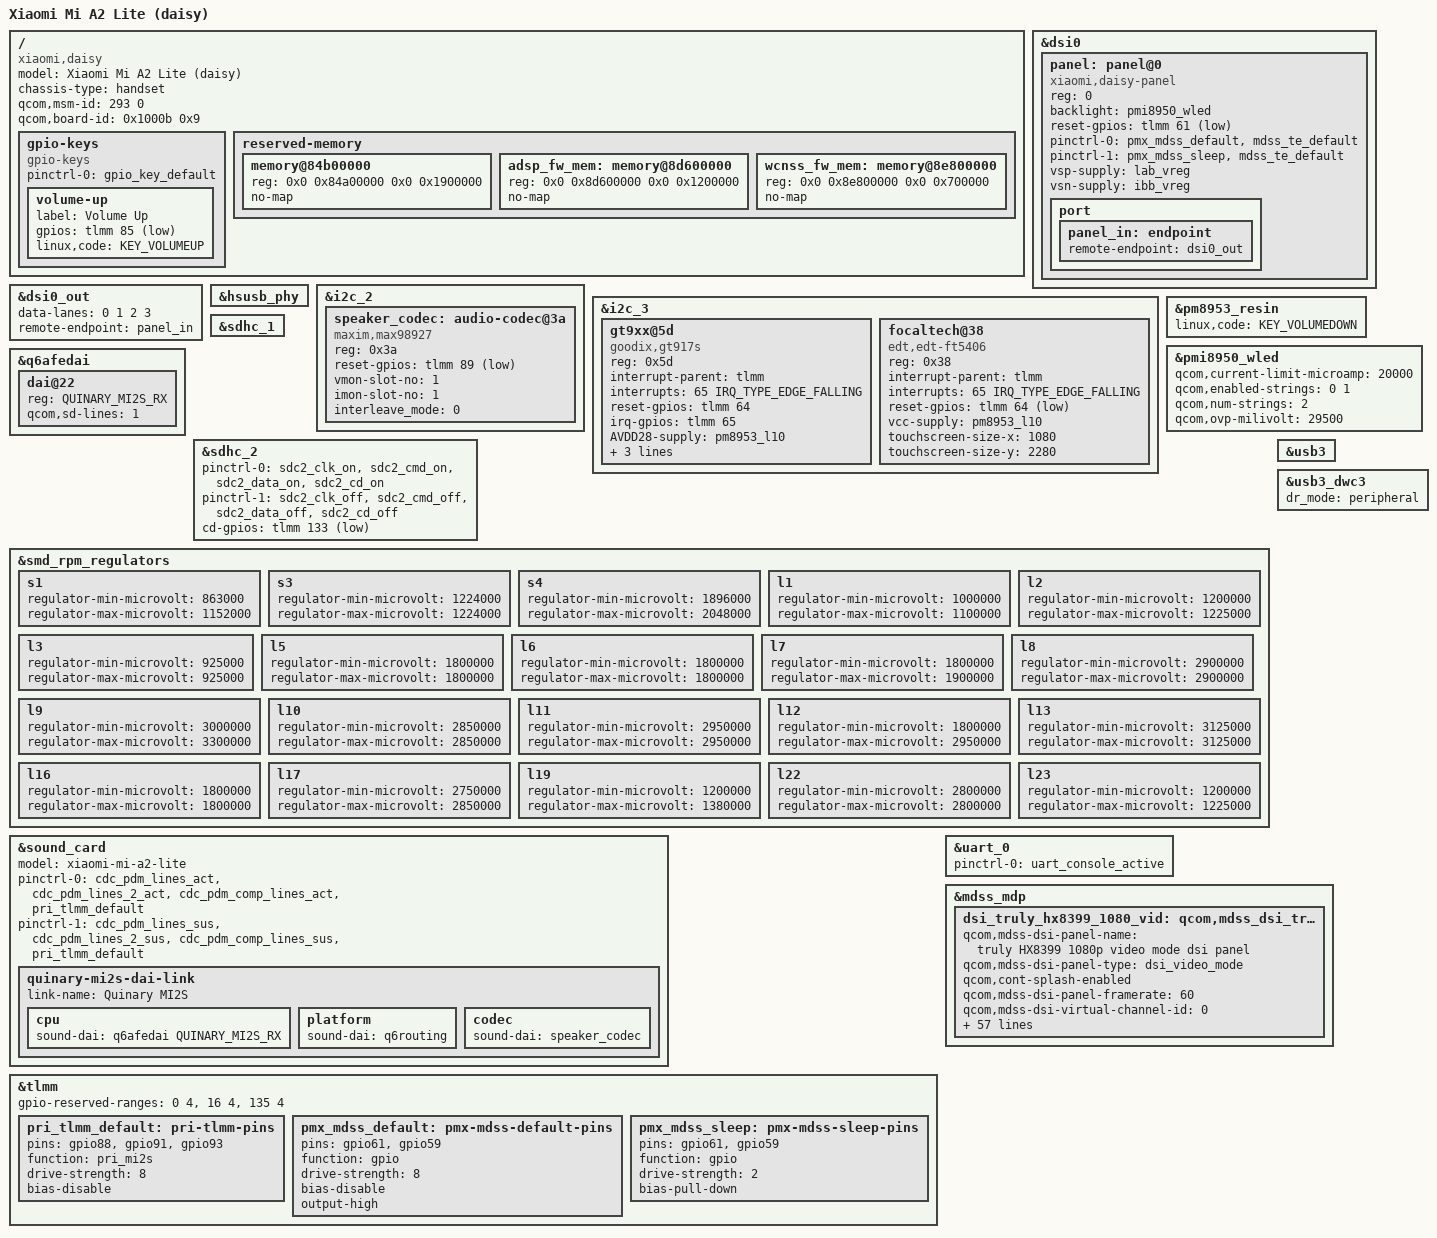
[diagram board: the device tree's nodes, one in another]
/* Copyright (c) 2022 The Linux Foundation. All rights reserved.
 *
 * This program is free software; you can redistribute it and/or modify
 * it under the terms of the GNU General Public License version 2 and
 * only version 2 as published by the Free Software Foundation.
 *
 * This program is distributed in the hope that it will be useful,
 * but WITHOUT ANY WARRANTY; without even the implied warranty of
 * MERCHANTABILITY or FITNESS FOR A PARTICULAR PURPOSE.  See the
 * GNU General Public License for more details.
 */
/dts-v1/;

#include "msm8953-pm8953.dtsi"
#include "pmi8950.dtsi"

#include <dt-bindings/gpio/gpio.h>
#include <dt-bindings/leds/common.h>

/ {
	compatible = "xiaomi,daisy", "qcom,msm8953";
	model = "Xiaomi Mi A2 Lite (daisy)";
	chassis-type = "handset";
	qcom,msm-id = <293 0>;
	qcom,board-id= <0x1000b 0x9>;

	gpio-keys {
		compatible = "gpio-keys";

		pinctrl-names = "default";
		pinctrl-0 = <&gpio_key_default>;

		volume-up {
			label = "Volume Up";
			gpios = <&tlmm 85 GPIO_ACTIVE_LOW>;
			linux,code = <KEY_VOLUMEUP>;
		};
	};

	reserved-memory {
		/delete-node/memory@85b00000;

		memory@84b00000 {
			reg = <0x0 0x84a00000 0x0 0x1900000>;
			no-map;
		};

		adsp_fw_mem: memory@8d600000 {
			reg = <0x0 0x8d600000 0x0 0x1200000>;
			no-map;
		};

		/delete-node/memory@8e700000;
		wcnss_fw_mem: memory@8e800000 {
			reg = <0x0 0x8e800000 0x0 0x700000>;
			no-map;
		};

		/*ramoops@9f00000 { // TODO Enable?
			compatible = "ramoops";
			reg = <0x0 0x9f00000 0x0 0x100000>;
			record-size = <0x10000>;
			console-size = <0x60000>;
			ftrace-size = <0x10000>;
			pmsg-size = <0x20000>;
			status = "okay";
		};*/
	};
};

&dsi0 {
	panel: panel@0 {
		compatible = "xiaomi,daisy-panel";
		reg = <0>;

		backlight = <&pmi8950_wled>;

		reset-gpios = <&tlmm 61 GPIO_ACTIVE_LOW>;

		pinctrl-names = "default", "sleep";
		pinctrl-0 = <&pmx_mdss_default &mdss_te_default>;
		pinctrl-1 = <&pmx_mdss_sleep &mdss_te_default>;

		vsp-supply = <&lab_vreg>;
		vsn-supply = <&ibb_vreg>;

		port {
			panel_in: endpoint {
				remote-endpoint = <&dsi0_out>;
			};
		};
	};
};

&dsi0_out {
	data-lanes = <0 1 2 3>;
	remote-endpoint = <&panel_in>;
};

&hsusb_phy {
	status = "okay";
};

&i2c_2 {
	status = "okay";

	speaker_codec: audio-codec@3a {
		compatible = "maxim,max98927";
		reg = <0x3a>;

		reset-gpios = <&tlmm 89 GPIO_ACTIVE_LOW>;

		vmon-slot-no = <1>;
		imon-slot-no = <1>;
		interleave_mode = <0>;

		#sound-dai-cells = <0>;
	};
};

&i2c_3 {
	status = "okay";

	gt9xx@5d {
		compatible = "goodix,gt917s";
		reg = <0x5d>;

		interrupt-parent = <&tlmm>;
		interrupts = <65 IRQ_TYPE_EDGE_FALLING>;

		reset-gpios = <&tlmm 64 GPIO_ACTIVE_HIGH>;
		irq-gpios = <&tlmm 65 GPIO_ACTIVE_HIGH>;

		AVDD28-supply = <&pm8953_l10>;
		VDDIO-supply = <&pm8953_l6>;

		touchscreen-size-x = <1080>;
		touchscreen-size-y = <2280>;
	};

	focaltech@38 {
		compatible = "edt,edt-ft5406", "edt,edt-ft5x06";
		reg = <0x38>;

		interrupt-parent = <&tlmm>;
		interrupts = <65 IRQ_TYPE_EDGE_FALLING>;

		reset-gpios = <&tlmm 64 GPIO_ACTIVE_LOW>;

		vcc-supply = <&pm8953_l10>;

		touchscreen-size-x = <1080>;
		touchscreen-size-y = <2280>;
	};
};

&pm8953_resin {
	status = "okay";
	linux,code = <KEY_VOLUMEDOWN>;
};

&pmi8950_wled {
	status = "okay";

	qcom,current-limit-microamp = <20000>;
	qcom,enabled-strings = <0 1>;
	qcom,num-strings = <2>;
	qcom,ovp-milivolt = <29500>;
};

&q6afedai {
	dai@22 {
		reg = <QUINARY_MI2S_RX>;
		qcom,sd-lines = <1>;
	};
};

&sdhc_1 {
	status = "okay";
};

&sdhc_2 {
	status = "okay";

	pinctrl-names = "default", "sleep";
	pinctrl-0 = <&sdc2_clk_on &sdc2_cmd_on &sdc2_data_on &sdc2_cd_on>;
	pinctrl-1 = <&sdc2_clk_off &sdc2_cmd_off &sdc2_data_off &sdc2_cd_off>;

	cd-gpios = <&tlmm 133 GPIO_ACTIVE_LOW>;
};

&smd_rpm_regulators {
	//TODO Supplies

	s1 {
		regulator-min-microvolt = <863000>;
		regulator-max-microvolt = <1152000>;
	};

	s3 {
		regulator-min-microvolt = <1224000>;
		regulator-max-microvolt = <1224000>;
	};

	s4 {
		regulator-min-microvolt = <1896000>;
		regulator-max-microvolt = <2048000>;
	};

	l1 {
		regulator-min-microvolt = <1000000>;
		regulator-max-microvolt = <1100000>;
	};

	l2 {
		regulator-min-microvolt = <1200000>;
		regulator-max-microvolt = <1225000>;
	};

	l3 {
		regulator-min-microvolt = <925000>;
		regulator-max-microvolt = <925000>;
	};

	l5 {
		regulator-min-microvolt = <1800000>;
		regulator-max-microvolt = <1800000>;
	};

	l6 {
		regulator-min-microvolt = <1800000>;
		regulator-max-microvolt = <1800000>;
	};

	l7 {
		regulator-min-microvolt = <1800000>;
		regulator-max-microvolt = <1900000>;
	};

	l8 {
		regulator-min-microvolt = <2900000>;
		regulator-max-microvolt = <2900000>;
	};

	l9 {
		regulator-min-microvolt = <3000000>;
		regulator-max-microvolt = <3300000>;
	};

	l10 {
		regulator-min-microvolt = <2850000>;
		regulator-max-microvolt = <2850000>;
	};

	l11 {
		regulator-min-microvolt = <2950000>;
		regulator-max-microvolt = <2950000>;
	};

	l12 {
		regulator-min-microvolt = <1800000>;
		regulator-max-microvolt = <2950000>;
	};

	l13 {
		regulator-min-microvolt = <3125000>;
		regulator-max-microvolt = <3125000>;
	};

	l16 {
		regulator-min-microvolt = <1800000>;
		regulator-max-microvolt = <1800000>;
	};

	l17 {
		regulator-min-microvolt = <2750000>;
		regulator-max-microvolt = <2850000>;
	};

	l19 {
		regulator-min-microvolt = <1200000>;
		regulator-max-microvolt = <1380000>;
	};

	l22 {
		regulator-min-microvolt = <2800000>;
		regulator-max-microvolt = <2800000>;
	};

	l23 {
		regulator-min-microvolt = <1200000>;
		regulator-max-microvolt = <1225000>;
	};
};

&sound_card {
	status = "okay";

	model = "xiaomi-mi-a2-lite";

	pinctrl-names = "default", "sleep";
	pinctrl-0 = <&cdc_pdm_lines_act &cdc_pdm_lines_2_act &cdc_pdm_comp_lines_act &pri_tlmm_default>;
	pinctrl-1 = <&cdc_pdm_lines_sus &cdc_pdm_lines_2_sus &cdc_pdm_comp_lines_sus &pri_tlmm_default>;

	quinary-mi2s-dai-link {
		link-name = "Quinary MI2S";
		cpu {
			sound-dai = <&q6afedai QUINARY_MI2S_RX>;
		};

		platform {
			sound-dai = <&q6routing>;
		};

		codec {
			sound-dai = <&speaker_codec>;
		};
	};
};

&tlmm {
	gpio-reserved-ranges = <0 4>, <16 4>, <135 4>;

	pri_tlmm_default: pri-tlmm-pins {
		pins = "gpio88", "gpio91", "gpio93";
		function = "pri_mi2s";
		drive-strength = <8>;
		bias-disable;
	};

	pmx_mdss_default: pmx-mdss-default-pins {
		pins = "gpio61", "gpio59";
		function = "gpio";
		drive-strength = <8>;
		bias-disable;
		output-high;
	};

	pmx_mdss_sleep: pmx-mdss-sleep-pins {
		pins = "gpio61", "gpio59";
		function = "gpio";
		drive-strength = <2>;
		bias-pull-down;
	};
};

&uart_0 {
	status = "okay";
	pinctrl-names = "default";
	pinctrl-0 = <&uart_console_active>;
};

&usb3 {
	status = "okay";
};

&usb3_dwc3 {
	dr_mode = "peripheral";
};

&mdss_mdp {
	dsi_truly_hx8399_1080_vid: qcom,mdss_dsi_truly_hx8399_1080p_video {
		qcom,mdss-dsi-panel-name = "truly HX8399 1080p video mode dsi panel";
		qcom,mdss-dsi-panel-type = "dsi_video_mode";
		qcom,cont-splash-enabled;
		qcom,mdss-dsi-panel-framerate = <60>;
		qcom,mdss-dsi-virtual-channel-id = <0>;
		qcom,mdss-dsi-stream = <0>;
		qcom,mdss-dsi-panel-width = <1080>;
		qcom,mdss-dsi-panel-height = <1920>;
		qcom,mdss-dsi-h-front-porch = <90>;
		qcom,mdss-dsi-h-back-porch = <60>;
		qcom,mdss-dsi-h-pulse-width = <20>;
		qcom,mdss-dsi-h-sync-skew = <0>;
		qcom,mdss-dsi-v-front-porch = <9>;
		qcom,mdss-dsi-v-back-porch = <3>;
		qcom,mdss-dsi-v-pulse-width = <4>;
		qcom,mdss-dsi-h-left-border = <0>;
		qcom,mdss-dsi-h-right-border = <0>;
		qcom,mdss-dsi-v-top-border = <0>;
		qcom,mdss-dsi-v-bottom-border = <0>;
		qcom,mdss-dsi-bpp = <24>;
		qcom,mdss-dsi-underflow-color = <0xff>;
		qcom,mdss-dsi-border-color = <0>;
		qcom,mdss-dsi-h-sync-pulse = <0>;
		qcom,mdss-dsi-traffic-mode = "burst_mode";
		qcom,mdss-dsi-bllp-eof-power-mode;
		qcom,mdss-dsi-bllp-power-mode;
		qcom,mdss-dsi-lane-0-state;
		qcom,mdss-dsi-lane-1-state;
		qcom,mdss-dsi-lane-2-state;
		qcom,mdss-dsi-lane-3-state;
		qcom,mdss-dsi-panel-timings = [f9 3d 34 00 58 4d 36 3f 53 03 04 00];
		qcom,mdss-dsi-t-clk-post = <0x02>;
		qcom,mdss-dsi-t-clk-pre = <0x2d>;
		qcom,mdss-dsi-bl-min-level = <160>;
		qcom,mdss-dsi-bl-max-level = <3562>;
		qcom,mdss-dsi-dma-trigger = "trigger_sw";
		qcom,mdss-dsi-mdp-trigger = "none";
                qcom,mdss-pan-physical-width-dimension = <69>;
                qcom,mdss-pan-physical-height-dimension = <122>;
		qcom,mdss-dsi-on-command = [
			39 01 00 00 00 00 04
			B9 FF 83 99
			39 01 00 00 00 00 10
			B1 00 04 6C 8C 01 32
			22 11 11 58 62 56 73
			02 02
			39 01 00 00 00 00 0c
			B2 00 80 80 AE 05 07
			5A 11 10 10 00
			39 01 00 00 00 00 2d
			B4 00 ff 00 A0 00 A0
			00 00 08 00 00 02 00
			24 02 04 0C 33 06 00
			00 00 a2 88 00 A0 00
			A0 00 00 08 00 00 02
			00 24 02 04 0C 00 00
			00 a2 08
			39 01 00 00 00 00 22
			D3 00 00 00 00 00 00
			06 00 32 10 05 00 05
			00 00 00 00 00 00 00
			00 00 00 01 00 05 05
			03 00 00 00 05 40
			39 01 00 00 00 00 21
			D5 18 18 00 00 00 00
			00 00 19 19 18 18 00
			00 00 00 00 00 00 00
			01 00 03 02 20 21 2F
			2F 30 30 31 31
			39 01 00 00 00 00 21
			D6 18 18 40 40 40 40
			40 40 18 18 19 19 40
			40 40 40 40 40 40 40
			02 03 00 01 21 20 2F
			2F 30 30 31 31
			39 01 00 00 00 00 11
			D8 00 00 00 00 00 00
			00 00 00 00 00 00 00
			00 00 00
			39 01 00 00 00 00 02
			BD 01
			39 01 00 00 00 00 11
			D8 00 00 00 00 00 00
			00 00 00 00 00 00 00
			00 00 00
			39 01 00 00 00 00 02
			BD 02
			39 01 00 00 00 00 09
			D8 c0 00 0a 3f c0 00
			0a 3f
			39 01 00 00 00 00 02
			BD 00
			39 01 00 00 00 00 37
			E0 01 14 20 19 3C 44
			52 4F 57 61 69 6E 75
			7B 83 85 89 90 92 97
			8B 98 9B 51 4E 59 65
			01 14 20 19 3C 44 52
			4F 57 61 69 6F 75 7C
			83 86 8A 91 92 98 8B
			98 9C 51 4E 5A 65
			39 01 00 00 00 00 02
			BD 00
			39 01 00 00 00 00 2C
			C1 01 00 08 10 18 20
			27 2F 37 3F 47 4F 56
			5F 67 6E 76 7E 86 8E
			96 9E A6 AF B6 BE C6
			CD D6 DE E7 EF F8 FF
			15 87 86 0F A9 11 0E
			12 C0
			39 01 00 00 00 00 02
			BD 01
			39 01 00 00 00 00 2B
			C1 00 08 10 18 20 27
			2F 38 3F 47 4F 57 5F
			67 6F 77 7F 87 90 98
			9F A7 AF B7 BE C7 CE
			D6 DE E7 EF F7 FF 05
			58 AA BA B0 94 CE C7
			C0
			39 01 00 00 00 00 02
			BD 02
			39 01 00 00 00 00 2B
			C1 00 08 0F 17 1F 27
			30 39 41 49 52 5A 62
			6B 73 7B 83 8C 93 9B
			A3 AB B3 BB C3 CB D3
			DA E2 EA F2 F9 FF 0F
			E6 71 D9 4E ED 82 82
			C0
			39 01 00 00 00 00 02
			BD 00
			39 01 00 00 00 00 02
			CC 08
			39 01 00 00 00 00 02
			D2 22
			39 01 00 00 00 00 04
			C9 03 00 0A
			39 01 00 00 00 00 03
			51 00 00
			15 01 00 00 00 00 02
			53 24
			15 01 00 00 0a 00 02
			55 00
			05 01 00 00 00 00 02
			34 00
			05 01 00 00 78 00 02
			11 00
			39 01 00 00 00 00 02
			D0 39
			05 01 00 00 00 00 02
			29 00
		];
		qcom,mdss-dsi-off-command = [
			05 01 00 00 32 00 02
			28 00
			05 01 00 00 64 00 02
			10 00
			39 01 00 00 00 00 04
			B9 ff 83 99
			39 01 00 00 00 00 02
			b1 01
		];
		qcom,mdss-dsi-on-command-state = "dsi_lp_mode";
		qcom,mdss-dsi-off-command-state = "dsi_lp_mode";
		qcom,mdss-dsi-bl-pmic-control-type = "bl_ctrl_dcs";
		qcom,mdss-dsi-reset-sequence = <1 20>, <0 10>, <1 20>;
		qcom,mdss-dsi-tx-eot-append;
		qcom,panel-supply-entries = <&dsi_panel_pwr_supply>;
		qcom,mdss-dsi-panel-status-command = [06 01 00 01 05 00 02 D0 08];
		qcom,mdss-dsi-panel-status-command-state = "dsi_hs_mode";
		qcom,mdss-dsi-panel-status-check-mode = "reg_read_hx8399";
		qcom,mdss-dsi-panel-status-value = <0x39 0xc7 0x7b>;
		qcom,mdss-dsi-panel-status-read-length = <3>;
		qcom,esd-check-enabled;
	};
};
